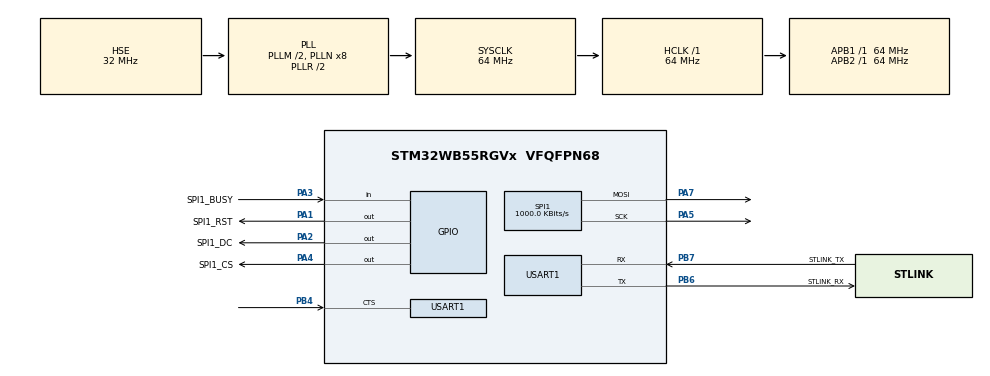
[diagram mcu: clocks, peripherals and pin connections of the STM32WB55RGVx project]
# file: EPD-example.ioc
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Mcu.Family=STM32WB
Mcu.Name=STM32WB55RGVx
Mcu.Package=VFQFPN68
NVIC.HSEM_IRQn=true\:0\:0\:false\:false\:true\:false\:true\:true
NVIC.PriorityGroup=NVIC_PRIORITYGROUP_4
OSC_IN.GPIO_Label=RCC_OSC_IN
OSC_IN.Mode=HSE-External-Oscillator
OSC_IN.Signal=RCC_OSC_IN
OSC_OUT.GPIO_Label=RCC_OSC_OUT
OSC_OUT.Mode=HSE-External-Oscillator
OSC_OUT.Signal=RCC_OSC_OUT
PA1.GPIO_Label=SPI1_RST
PA1.Signal=GPIO_Output
PA11.GPIO_Label=USB_DM
PA11.Signal=USB_DM
PA12.GPIO_Label=USB_DP
PA12.Signal=USB_DP
PA13.GPIO_Label=JTMS
PA13.Signal=SYS_JTMS-SWDIO
PA14.GPIO_Label=JTCK
PA14.Signal=SYS_JTCK-SWCLK
PA2.GPIO_Label=SPI1_DC
PA2.Signal=GPIO_Output
PA3.GPIO_Label=SPI1_BUSY
PA3.Signal=GPIO_Input
PA4.GPIO_Label=SPI1_CS
PA4.Signal=GPIO_Output
PA5.Mode=TX_Only_Simplex_Unidirect_Master
PA5.Signal=SPI1_SCK
PA7.Mode=TX_Only_Simplex_Unidirect_Master
PA7.Signal=SPI1_MOSI
PB3.GPIO_Label=JTDO
PB3.Signal=SYS_JTDO-SWO
PB4.Mode=CTS_Only
PB4.Signal=USART1_CTS
PB6.GPIO_Label=STLINK_RX
PB6.Mode=Asynchronous
PB6.Signal=USART1_TX
PB7.GPIO_Label=STLINK_TX
PB7.Mode=Asynchronous
PB7.Signal=USART1_RX
PC13.GPIO_Label=SYS_WKUP2
PC13.Signal=SYS_WKUP2
PC14-OSC32_IN.GPIO_Label=RCC_OSC32_IN
PC14-OSC32_IN.Mode=LSE-External-Oscillator
PC14-OSC32_IN.Signal=RCC_OSC32_IN
PC15-OSC32_OUT.GPIO_Label=RCC_OSC32_OUT
PC15-OSC32_OUT.Mode=LSE-External-Oscillator
PC15-OSC32_OUT.Signal=RCC_OSC32_OUT
ProjectManager.HeapSize=0x200
ProjectManager.StackSize=0x400
ProjectManager.TargetToolchain=CMake
RCC.ADCFreq_Value=64000000
RCC.AHB2CLKDivider=RCC_SYSCLK_DIV2
RCC.AHBFreq_Value=64000000
RCC.APB1Freq_Value=64000000
RCC.APB1TimFreq_Value=64000000
RCC.APB2Freq_Value=64000000
RCC.APB2TimFreq_Value=64000000
RCC.APB3Freq_Value=16000000
RCC.CortexFreq_Value=64000000
RCC.HCLKFreq_Value=64000000
RCC.HSE_VALUE=32000000
RCC.HSI48_VALUE=48000000
RCC.HSI_VALUE=16000000
RCC.MSIClockRange=RCC_MSIRANGE_10
RCC.PLLM=RCC_PLLM_DIV2
RCC.PLLSourceVirtual=RCC_PLLSOURCE_HSE
RCC.SMPSCLockSelectionVirtual=RCC_SMPSCLKSOURCE_HSI
RCC.SMPSCLockSelectionVirtualVirtual=RCC_SMPSCLKSOURCE_HSI
RCC.SMPSDivider=1
RCC.SYSCLKFreq_VALUE=64000000
RCC.SYSCLKSource=RCC_SYSCLKSOURCE_PLLCLK
RCC.USBFreq_Value=64000000
RCC.VCOOutputFreq_Value=128000000
SPI1.BaudRatePrescaler=SPI_BAUDRATEPRESCALER_64
SPI1.CalculateBaudRate=1000.0 KBits/s
SPI1.DataSize=SPI_DATASIZE_8BIT
SPI1.Direction=SPI_DIRECTION_2LINES
SPI1.Mode=SPI_MODE_MASTER
SPI1.NSSPMode=SPI_NSS_PULSE_DISABLE
SPI1.VirtualType=VM_MASTER
USART1.VirtualMode-Asynchronous=VM_ASYNC
VP_HSEM_VS_HSEM.Mode=HSEM_Activate
VP_MEMORYMAP_VS_MEMORYMAP.Mode=CurAppReg
board=NUCLEO-WB55RG

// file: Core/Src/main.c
/* USER CODE BEGIN Header */
/**
  ******************************************************************************
  * @file           : main.c
  * @brief          : Main program body
  ******************************************************************************
  * @attention
  *
  * Copyright (c) 2026 STMicroelectronics.
  * All rights reserved.
  *
  * This software is licensed under terms that can be found in the LICENSE file
  * in the root directory of this software component.
  * If no LICENSE file comes with this software, it is provided AS-IS.
  *
  ******************************************************************************
  */
/* USER CODE END Header */
#include "main.h"

/* USER CODE BEGIN Includes */
#include "EPD_Test.h"
#include "minimal_display.h"
/* USER CODE END Includes */

SPI_HandleTypeDef hspi1;

UART_HandleTypeDef huart1;

void SystemClock_Config(void);
void PeriphCommonClock_Config(void);
static void MX_GPIO_Init(void);
static void MX_SPI1_Init(void);
static void MX_USART1_UART_Init(void);

int main(void)
{

  /* MCU Configuration--------------------------------------------------------*/

  /* Reset of all peripherals, Initializes the Flash interface and the Systick. */
  HAL_Init();

  /* Configure the system clock */
  SystemClock_Config();

  /* Configure the peripherals common clocks */
  PeriphCommonClock_Config();

  /* Initialize all configured peripherals */
  MX_GPIO_Init();
  MX_SPI1_Init();
  MX_USART1_UART_Init();
  /* USER CODE BEGIN 2 */
  // EPD_test();
  /* Static text, then a counter redrawn every 10 s */
  Display_Init();
  uint32_t update_count = 0;
  /* USER CODE END 2 */

  /* Infinite loop */
  while (1)
  {

    /* USER CODE BEGIN 3 */
    HAL_Delay(10000);
    Display_Update(++update_count);
  }
  /* USER CODE END 3 */
}

void SystemClock_Config(void)
{
  RCC_OscInitTypeDef RCC_OscInitStruct = {0};
  RCC_ClkInitTypeDef RCC_ClkInitStruct = {0};

  /** Configure the main internal regulator output voltage
  */
  __HAL_PWR_VOLTAGESCALING_CONFIG(PWR_REGULATOR_VOLTAGE_SCALE1);

  /** Initializes the RCC Oscillators according to the specified parameters
  * in the RCC_OscInitTypeDef structure.
  */
  RCC_OscInitStruct.OscillatorType = RCC_OSCILLATORTYPE_HSI|RCC_OSCILLATORTYPE_HSE;
  RCC_OscInitStruct.HSEState = RCC_HSE_ON;
  RCC_OscInitStruct.HSIState = RCC_HSI_ON;
  RCC_OscInitStruct.HSICalibrationValue = RCC_HSICALIBRATION_DEFAULT;
  RCC_OscInitStruct.PLL.PLLState = RCC_PLL_ON;
  RCC_OscInitStruct.PLL.PLLSource = RCC_PLLSOURCE_HSE;
  RCC_OscInitStruct.PLL.PLLM = RCC_PLLM_DIV2;
  RCC_OscInitStruct.PLL.PLLN = 8;
  RCC_OscInitStruct.PLL.PLLP = RCC_PLLP_DIV2;
  RCC_OscInitStruct.PLL.PLLR = RCC_PLLR_DIV2;
  RCC_OscInitStruct.PLL.PLLQ = RCC_PLLQ_DIV2;
  if (HAL_RCC_OscConfig(&RCC_OscInitStruct) != HAL_OK)
  {
    Error_Handler();
  }

  /** Configure the SYSCLKSource, HCLK, PCLK1 and PCLK2 clocks dividers
  */
  RCC_ClkInitStruct.ClockType = RCC_CLOCKTYPE_HCLK4|RCC_CLOCKTYPE_HCLK2
                              |RCC_CLOCKTYPE_HCLK|RCC_CLOCKTYPE_SYSCLK
                              |RCC_CLOCKTYPE_PCLK1|RCC_CLOCKTYPE_PCLK2;
  RCC_ClkInitStruct.SYSCLKSource = RCC_SYSCLKSOURCE_PLLCLK;
  RCC_ClkInitStruct.AHBCLKDivider = RCC_SYSCLK_DIV1;
  RCC_ClkInitStruct.APB1CLKDivider = RCC_HCLK_DIV1;
  RCC_ClkInitStruct.APB2CLKDivider = RCC_HCLK_DIV1;
  RCC_ClkInitStruct.AHBCLK2Divider = RCC_SYSCLK_DIV2;
  RCC_ClkInitStruct.AHBCLK4Divider = RCC_SYSCLK_DIV1;

  if (HAL_RCC_ClockConfig(&RCC_ClkInitStruct, FLASH_LATENCY_3) != HAL_OK)
  {
    Error_Handler();
  }
}

void PeriphCommonClock_Config(void)
{
  RCC_PeriphCLKInitTypeDef PeriphClkInitStruct = {0};

  /** Initializes the peripherals clock
  */
  PeriphClkInitStruct.PeriphClockSelection = RCC_PERIPHCLK_SMPS;
  PeriphClkInitStruct.SmpsClockSelection = RCC_SMPSCLKSOURCE_HSI;
  PeriphClkInitStruct.SmpsDivSelection = RCC_SMPSCLKDIV_RANGE0;

  if (HAL_RCCEx_PeriphCLKConfig(&PeriphClkInitStruct) != HAL_OK)
  {
    Error_Handler();
  }
}

static void MX_SPI1_Init(void)
{

  /* SPI1 parameter configuration*/
  hspi1.Instance = SPI1;
  hspi1.Init.Mode = SPI_MODE_MASTER;
  hspi1.Init.Direction = SPI_DIRECTION_2LINES;
  hspi1.Init.DataSize = SPI_DATASIZE_8BIT;
  hspi1.Init.CLKPolarity = SPI_POLARITY_LOW;
  hspi1.Init.CLKPhase = SPI_PHASE_1EDGE;
  hspi1.Init.NSS = SPI_NSS_SOFT;
  hspi1.Init.BaudRatePrescaler = SPI_BAUDRATEPRESCALER_64;
  hspi1.Init.FirstBit = SPI_FIRSTBIT_MSB;
  hspi1.Init.TIMode = SPI_TIMODE_DISABLE;
  hspi1.Init.CRCCalculation = SPI_CRCCALCULATION_DISABLE;
  hspi1.Init.CRCPolynomial = 7;
  hspi1.Init.CRCLength = SPI_CRC_LENGTH_DATASIZE;
  hspi1.Init.NSSPMode = SPI_NSS_PULSE_DISABLE;
  if (HAL_SPI_Init(&hspi1) != HAL_OK)
  {
    Error_Handler();
  }

}

static void MX_USART1_UART_Init(void)
{

  huart1.Instance = USART1;
  huart1.Init.BaudRate = 115200;
  huart1.Init.WordLength = UART_WORDLENGTH_8B;
  huart1.Init.StopBits = UART_STOPBITS_1;
  huart1.Init.Parity = UART_PARITY_NONE;
  huart1.Init.Mode = UART_MODE_TX_RX;
  huart1.Init.HwFlowCtl = UART_HWCONTROL_CTS;
  huart1.Init.OverSampling = UART_OVERSAMPLING_16;
  huart1.Init.OneBitSampling = UART_ONE_BIT_SAMPLE_DISABLE;
  huart1.Init.ClockPrescaler = UART_PRESCALER_DIV1;
  huart1.AdvancedInit.AdvFeatureInit = UART_ADVFEATURE_NO_INIT;
  if (HAL_UART_Init(&huart1) != HAL_OK)
  {
    Error_Handler();
  }
  if (HAL_UARTEx_SetTxFifoThreshold(&huart1, UART_TXFIFO_THRESHOLD_1_8) != HAL_OK)
  {
    Error_Handler();
  }
  if (HAL_UARTEx_SetRxFifoThreshold(&huart1, UART_RXFIFO_THRESHOLD_1_8) != HAL_OK)
  {
    Error_Handler();
  }
  if (HAL_UARTEx_DisableFifoMode(&huart1) != HAL_OK)
  {
    Error_Handler();
  }

}

static void MX_GPIO_Init(void)
{
  GPIO_InitTypeDef GPIO_InitStruct = {0};

  /* GPIO Ports Clock Enable */
  __HAL_RCC_GPIOC_CLK_ENABLE();
  __HAL_RCC_GPIOA_CLK_ENABLE();
  __HAL_RCC_GPIOB_CLK_ENABLE();

  /*Configure GPIO pin Output Level */
  HAL_GPIO_WritePin(GPIOA, SPI1_RST_Pin|SPI1_DC_Pin|SPI1_CS_Pin, GPIO_PIN_RESET);

  /*Configure GPIO pins : SPI1_RST_Pin SPI1_DC_Pin SPI1_CS_Pin */
  GPIO_InitStruct.Pin = SPI1_RST_Pin|SPI1_DC_Pin|SPI1_CS_Pin;
  GPIO_InitStruct.Mode = GPIO_MODE_OUTPUT_PP;
  GPIO_InitStruct.Pull = GPIO_NOPULL;
  GPIO_InitStruct.Speed = GPIO_SPEED_FREQ_LOW;
  HAL_GPIO_Init(GPIOA, &GPIO_InitStruct);

  /*Configure GPIO pin : SPI1_BUSY_Pin */
  GPIO_InitStruct.Pin = SPI1_BUSY_Pin;
  GPIO_InitStruct.Mode = GPIO_MODE_INPUT;
  GPIO_InitStruct.Pull = GPIO_NOPULL;
  HAL_GPIO_Init(SPI1_BUSY_GPIO_Port, &GPIO_InitStruct);

  /*Configure GPIO pins : USB_DM_Pin USB_DP_Pin */
  GPIO_InitStruct.Pin = USB_DM_Pin|USB_DP_Pin;
  GPIO_InitStruct.Mode = GPIO_MODE_AF_PP;
  GPIO_InitStruct.Pull = GPIO_NOPULL;
  GPIO_InitStruct.Speed = GPIO_SPEED_FREQ_LOW;
  GPIO_InitStruct.Alternate = GPIO_AF10_USB;
  HAL_GPIO_Init(GPIOA, &GPIO_InitStruct);

}

void Error_Handler(void)
{
  __disable_irq();
  while (1)
  {
  }
}
